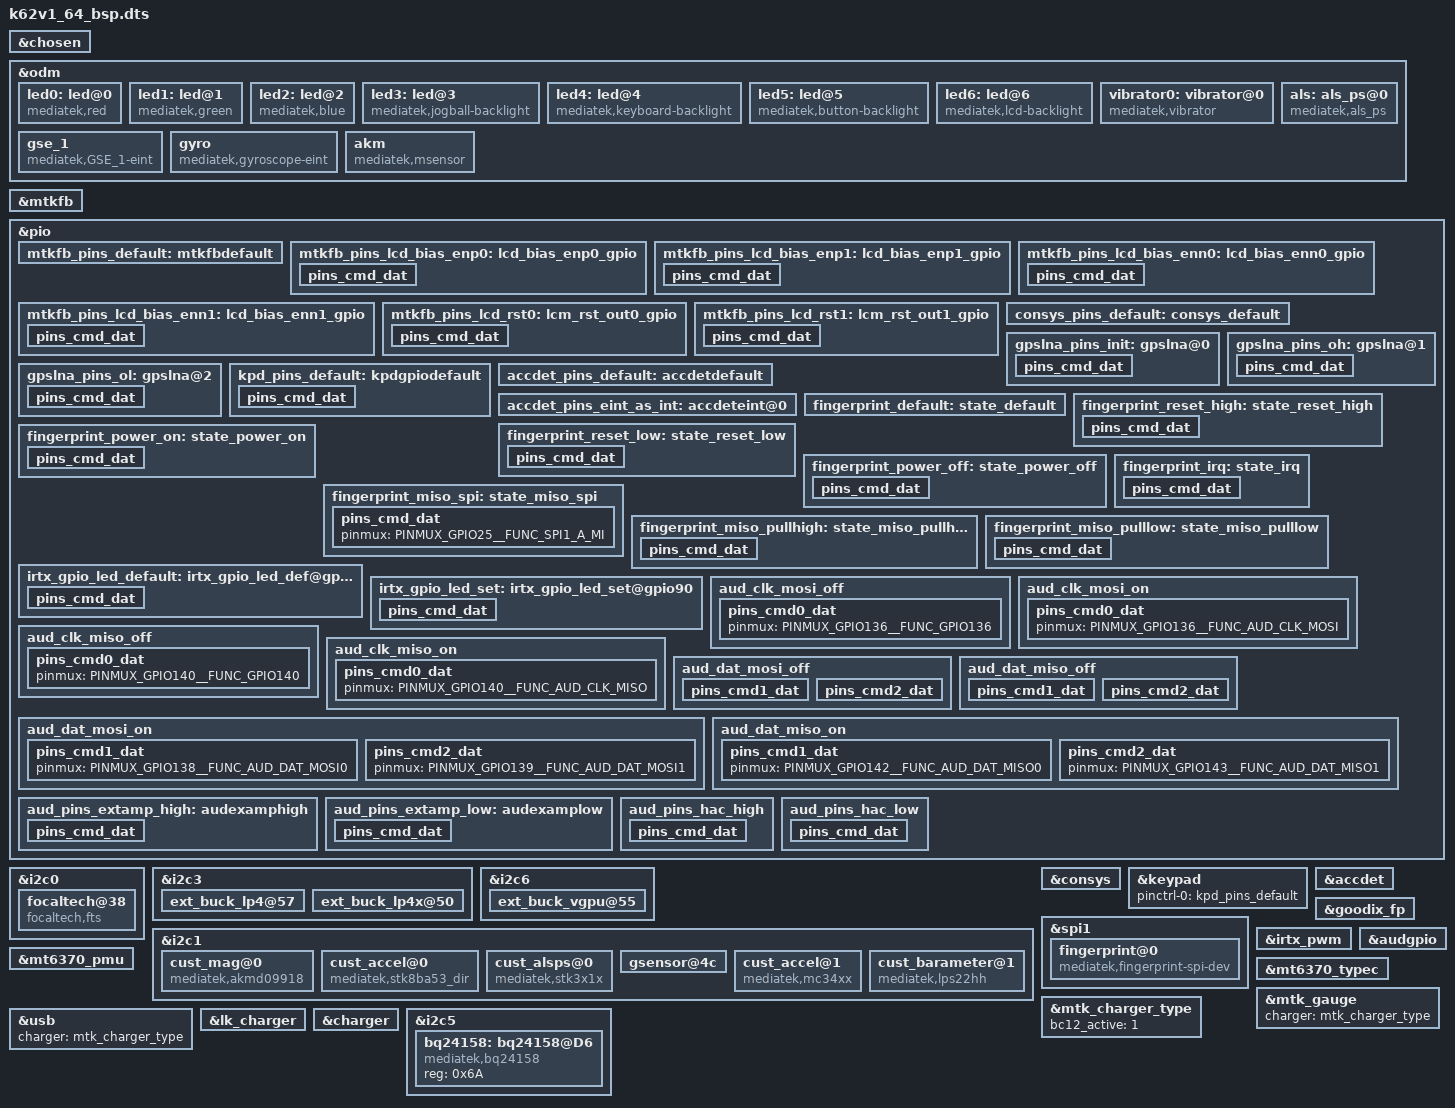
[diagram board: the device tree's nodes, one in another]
// SPDX-License-Identifier: GPL-2.0+

#include <dt-bindings/interrupt-controller/arm-gic.h>
#include <dt-bindings/interrupt-controller/irq.h>
#include <dt-bindings/pinctrl/mt6765-pinfunc.h>
#include <dt-bindings/clock/mt6765-clk.h>

/dts-v1/;
/plugin/;

/* chosen */
&chosen {

	/* fpga may has no lk, we need to specify display info here */
	/* fb buffer is reserved using this dts by memory node above */
	atag,videolfb-fb_base_h = <0x0>;
	atag,videolfb-fb_base_l = <0x5e605000>;
	atag,videolfb-islcmfound = <1>;
	/* because no lk, so lcm is not inited */
	atag,videolfb-islcm_inited = <0>;
	atag,videolfb-fps= <6000>;
	atag,videolfb-vramSize= <0x017bb000>;
	atag,videolfb-lcmname= "nt35695B_fhd_dsi_cmd_auo_rt5081_drv";
};

&odm {
	led0:led@0 {
		compatible = "mediatek,red";
		/* Begin modified by bitao.xiong for task-9796564 on 2020-08-20 */
		led_mode = <3>;
		data = <2>;
		/* End modified by bitao.xiong for task-9796564 on 2020-08-20 */
		pwm_config = <0 0 0 0 0>;
	};
	led1:led@1 {
		compatible = "mediatek,green";
		led_mode = <0>;
		data = <1>;
		pwm_config = <0 0 0 0 0>;
	};
	led2:led@2 {
		compatible = "mediatek,blue";
		led_mode = <0>;
		data = <1>;
		pwm_config = <0 0 0 0 0>;
	};
	led3:led@3 {
		compatible = "mediatek,jogball-backlight";
		led_mode = <0>;
		data = <1>;
		pwm_config = <0 0 0 0 0>;
	};
	led4:led@4 {
		compatible = "mediatek,keyboard-backlight";
		led_mode = <0>;
		data = <1>;
		pwm_config = <0 0 0 0 0>;
	};
	led5:led@5 {
		compatible = "mediatek,button-backlight";
		led_mode = <0>;
		data = <1>;
		pwm_config = <0 0 0 0 0>;
	};
//begin modified by xiongbo.huang for backlight frequency on 20200601
	led6:led@6 {
		compatible = "mediatek,lcd-backlight";
		led_mode = <5>;
		data = <1>;
		pwm_config = <0 0 0 0 0>;
	};
//end modified by xiongbo.huang for backlight frequency on 20200601
	vibrator0:vibrator@0 {
		compatible = "mediatek,vibrator";
		vib_timer = <25>;
		vib_limit = <9>;
		vib_vol= <9>;
	};

         als: als_ps@0 {
                compatible = "mediatek,als_ps";
	        interrupt-parent = <&pio>;
         	interrupts = <6 IRQ_TYPE_LEVEL_LOW 6 0>;
         	status = "okay";
         };
         gse_1: gse_1 {
         compatible = "mediatek,GSE_1-eint";
         };
         gyro: gyro {
               compatible = "mediatek,gyroscope-eint";
         };
         akm: akm{
               compatible = "mediatek,msensor";
         };
	
};

//begin add by xiongbo.huang for android r porting on 20200601
&mtkfb {
	pinctrl-names = "default", "lcd_bias_enp0_gpio", "lcd_bias_enp1_gpio","lcd_bias_enn0_gpio", "lcd_bias_enn1_gpio","lcm_rst_out0_gpio","lcm_rst_out1_gpio";
	pinctrl-0 = <&mtkfb_pins_default>;
	pinctrl-1 = <&mtkfb_pins_lcd_bias_enp0>;
	pinctrl-2 = <&mtkfb_pins_lcd_bias_enp1>;
	pinctrl-3 = <&mtkfb_pins_lcd_bias_enn0>;
	pinctrl-4 = <&mtkfb_pins_lcd_bias_enn1>;
	pinctrl-5 = <&mtkfb_pins_lcd_rst0>;
	pinctrl-6 = <&mtkfb_pins_lcd_rst1>;
	status = "okay";
};
&pio {
	mtkfb_pins_default: mtkfbdefault {
	};

	mtkfb_pins_lcd_bias_enp0: lcd_bias_enp0_gpio {
		pins_cmd_dat {
			pinmux = <PINMUX_GPIO164__FUNC_GPIO164>;
			slew-rate = <1>;
			output-low;
		};
	};

	mtkfb_pins_lcd_bias_enp1: lcd_bias_enp1_gpio {
		pins_cmd_dat {
			pinmux = <PINMUX_GPIO164__FUNC_GPIO164>;
			slew-rate = <1>;
			output-high;
		};
	};

	mtkfb_pins_lcd_bias_enn0: lcd_bias_enn0_gpio {
                   pins_cmd_dat {
                            pinmux = <PINMUX_GPIO166__FUNC_GPIO166>;
                            slew-rate = <1>;
                            output-low;
                   };
         };

         mtkfb_pins_lcd_bias_enn1: lcd_bias_enn1_gpio {
                   pins_cmd_dat {
                            pinmux = <PINMUX_GPIO166__FUNC_GPIO166>;
                            slew-rate = <1>;
                            output-high;
                   };
         };

         mtkfb_pins_lcd_rst0: lcm_rst_out0_gpio {
                   pins_cmd_dat {
                            pinmux = <PINMUX_GPIO45__FUNC_GPIO45>;
                            slew-rate = <1>;
                            output-low;
                   };
         };

         mtkfb_pins_lcd_rst1: lcm_rst_out1_gpio {
                   pins_cmd_dat {
                            pinmux = <PINMUX_GPIO45__FUNC_GPIO45>;
                            slew-rate = <1>;
                            output-high;
                   };
         };

};
&i2c0 {
		focaltech@38{
			compatible = "focaltech,fts";
			reg = <0x38>;
			interrupt-parent = <&pio>;
			interrupts = <0 IRQ_TYPE_EDGE_FALLING 0 0>;
			focaltech,reset-gpio = <&pio 46 0x0>;
			focaltech,irq-gpio = <&pio 0 0x0>;
			focaltech,max-touch-number = <5>;
			focaltech,display-coords =  <0 0 720 1440>;
			vtouch-supply = <&mt_pmic_vldo28_ldo_reg>;
			/*pinctrl-names = "pmx_ts_active","pmx_ts_suspend","pmx_ts_release";
			pinctrl-0 = <&ts_int_active &ts_reset_active>;
			pinctrl-1 = <&ts_int_suspend &ts_reset_suspend>;
			pinctrl-2 = <&ts_release>;*/

			/*
			focaltech,have-key;
			focaltech,key-number = <3>;
			focaltech,keys = <139 102 158>;
			focaltech,key-x-coords = <200 600 800>;
			focaltech,key-y-coords = <2000 2000 2000>;
			*/
		};
	};
//end add by xiongbo.huang for android r porting on 20200601
&i2c3 {
	ext_buck_lp4@57 {
		regulator-name ="ext_buck_vdd2";
		regulator-min-microvolt = <300000>;
		regulator-max-microvolt = <1300000>;
		vsel_pin = <0>;
	};

	ext_buck_lp4x@50 {
		regulator-name ="ext_buck_vddq";
		regulator-min-microvolt = <300000>;
		regulator-max-microvolt = <1300000>;
		vsel_pin = <1>;
	};
};

&i2c6 {
	ext_buck_vgpu@55 {
		regulator-name ="ext_buck_vgpu";
		regulator-min-microvolt = <300000>;
		regulator-max-microvolt = <1300000>;
		vsel_pin = <2>;
	};
};

&i2c1 {
/*  start sensor */
         cust_mag@0 {
                 compatible              = "mediatek,akmd09918";
                 /* i2c_num              = <1>; */
                 /* i2c_addr             = <0x0C 0 0 0>; */
                 direction               = <4>;
                 power_id                = <0xffff>;
                 power_vol               = <0>;
                 /* is_batch_supported   = <0>; */
         };
     	cust_accel@0 {
         compatible = "mediatek,stk8ba53_dir";
         //i2c_num = <1>;
         direction = <1>;
         power_id = <0xffff>;
         power_vol = <0>;
         firlen = <0>;
         is_batch_supported = <0>;
         };
         cust_alsps@0 {
         compatible = "mediatek,stk3x1x";
         /*i2c_num = <1>;
         i2c_addr = <0x51 0 0 0>;*/
         polling_mode_ps = <0>;
         polling_mode_als = <1>;
         power_id = <0xffff>;
         power_vol = <0>;
         als_level = <0 328 861 1377 3125 7721 7767 12621 23062 28430 33274 47116 57694 57694 65535>;
         als_value = <0 133 304 502 1004 2005 3058 5005 8008 10010 12000 16000 20000 20000 20000 20000>;
         ps_threshold_high = <26>;
         ps_threshold_low = <21>;
         is_batch_supported_ps = <0>;
         is_batch_supported_als = <0>;
         };

         gsensor@4c {
                 i2c_num = <1>;
                 direction = <6>;
                 power_id = <0xffff>;
                 power_vol = <0>;
                 firlen = <16>;
                 is_batch_supported = <1>;
         };
         cust_accel@1 {
                 compatible = "mediatek,mc34xx";
                 //i2c_num       = <1>;
                 direction = <1>;
                 power_id = <0xffff>;
                 power_vol = <0>;
                 firlen = <0>;
                 is_batch_supported = <0>;
         };

         cust_barameter@1 {
                 compatible = "mediatek,lps22hh";
		 i2c_num= <1>;
                 direction = <1>;
                 power_id = <0xffff>;
                 power_vol = <0>;
                 firlen = <1>;
                 is_batch_supported = <1>;
         };
/* end sensor */
/* end sensor */
};



//Begin modified by yaoting.wei for GNSS task 8177692 on 2019/07/29
/* CONSYS GPIO standardization */
&pio {
	consys_pins_default: consys_default {
	};
	gpslna_pins_init: gpslna@0 {
		pins_cmd_dat {
			pinmux = <PINMUX_GPIO76__FUNC_GPIO76>;
			slew-rate = <0>;
			bias-disable;
			output-low;
		};
	};
	gpslna_pins_oh: gpslna@1 {
		pins_cmd_dat {
			pinmux = <PINMUX_GPIO76__FUNC_GPIO76>;
			slew-rate = <1>;
			output-high;
		};
	};
	gpslna_pins_ol: gpslna@2 {
		pins_cmd_dat {
			pinmux = <PINMUX_GPIO76__FUNC_GPIO76>;
			slew-rate = <1>;
			output-low;
		};
	};
};
&consys {
	pinctrl-names = "default", "gps_lna_state_init",
		"gps_lna_state_oh", "gps_lna_state_ol";
	pinctrl-0 = <&consys_pins_default>;
	pinctrl-1 = <&gpslna_pins_init>;
	pinctrl-2 = <&gpslna_pins_oh>;
	pinctrl-3 = <&gpslna_pins_ol>;
	status = "okay";
};
/* CONSYS end */
//End modified by yaoting.wei for GNSS  task 8177692 on 2019/07/29

&keypad {
	pinctrl-names = "default";
	pinctrl-0 = <&kpd_pins_default>;
};

&pio {
	kpd_pins_default: kpdgpiodefault {
		pins_cmd_dat {
			pinmux = <PINMUX_GPIO93__FUNC_KPCOL0>;
			bias-pull-up = <MTK_PUPD_SET_R1R0_10>;
			output-low;
			input-schmitt-enable;
		};
	};
};


/* accdet start */
/* Begin Modified by chunyang.zhou for 7821596 :enable headset accdet config */
&accdet {
	/* accdet micbias voltage: 0x07,2.7v;0x05,2.5v;0x02,1.9v */
	accdet-mic-vol = <6>;
	headset-mode-setting = <0x500 0x500 1 0x1f0 0x2000 0x800 0x20 0x44>;
	accdet-plugout-debounce = <20>;
	/*1:ACC mode, 2:low cost without in bias, 6:low cost with in bias*/
	accdet-mic-mode = <1>;
	/* eint_level_trigger: 8,LEVEL_LOW(default);4,LEVEL_HIGH;others,LEVEL_LOW */
	headset-eint-level-pol = <8>;
	/*0--MD_MAX--UP_MAX--DW_MAX*/
	headset-three-key-threshold = <0 80 220 400>;
	headset-three-key-threshold-CDD = <0 121 192 600>;
	/*0--MD_MAX--VOICE_MAX--UP_MAX--DW_MAX*/
	headset-four-key-threshold = <0 58 121 192 400>;
	pinctrl-names = "default", "state_eint_as_int";
	pinctrl-0 = <&accdet_pins_default>;
	pinctrl-1 = <&accdet_pins_eint_as_int>;
	status = "okay";
};
/* End Modified by chunyang.zhou for 7821596 :enable headset accdet config */
&pio {
	accdet_pins_default: accdetdefault {
	};
	accdet_pins_eint_as_int: accdeteint@0 {
	};
};
/* accdet end */
/*End   Modified by fuhua.wang for audio-bring-up on 2019.07.31 task_id: 8188551 */

/* FINGERPRINT start */

/* FINGERPRINT end */

/* FINGERPRINT start */
/* Begin to modified by yuduan.xie on 2019.07.31 for 8177729 */
&spi1 {
	#address-cells = <1>;
	#size-cells = <0>;
	fingerprint@0 {
		compatible = "mediatek,fingerprint-spi-dev";
		reg = <0>;
		spi-max-frequency = <12000000>;
		netlink-event = <31>;
		status = "okay";
	};
};
&goodix_fp{
	pinctrl-names = "fp_default", "fp_reset_high", "fp_reset_low", "fp_power_on", "fp_power_off", "fp_irq", "miso_spi", "miso_pullhigh", "miso_pulllow";
	pinctrl-0 = <&fingerprint_default>;
	pinctrl-1 = <&fingerprint_reset_high>;
	pinctrl-2 = <&fingerprint_reset_low>;
	pinctrl-3 = <&fingerprint_power_on>;
	pinctrl-4 = <&fingerprint_power_off>;
	pinctrl-5 = <&fingerprint_irq>;

	pinctrl-6 = <&fingerprint_miso_spi>;
	pinctrl-7 = <&fingerprint_miso_pullhigh>;
	pinctrl-8 = <&fingerprint_miso_pulllow>;

	status = "okay";
};

&pio {
	fingerprint_default: state_default {

	};

	fingerprint_reset_high: state_reset_high{
		pins_cmd_dat {
			pinmux = <PINMUX_GPIO14__FUNC_GPIO14>;
			slew-rate = <1>;
			output-high;
		};
	};

	fingerprint_reset_low: state_reset_low{
		pins_cmd_dat {
			pinmux = <PINMUX_GPIO14__FUNC_GPIO14>;
			slew-rate = <1>;
			output-low;
		};
	};

	fingerprint_power_on: state_power_on{
		pins_cmd_dat {
			pinmux = <PINMUX_GPIO21__FUNC_GPIO21>;
			slew-rate = <1>;
			output-high;
		};
	};

	fingerprint_power_off: state_power_off{
		pins_cmd_dat {
			pinmux = <PINMUX_GPIO21__FUNC_GPIO21>;
			slew-rate = <1>;
			output-low;
		};
	};

	fingerprint_irq: state_irq{
		pins_cmd_dat {
			pinmux = <PINMUX_GPIO13__FUNC_GPIO13>;
			slew-rate = <0>;
			bias-pull-down = <11>;
		};
	};

	fingerprint_miso_spi: state_miso_spi {
		pins_cmd_dat {
			pinmux = <PINMUX_GPIO25__FUNC_SPI1_A_MI>;
		};
	};
	fingerprint_miso_pullhigh: state_miso_pullhigh {
		pins_cmd_dat {
			pinmux = <PINMUX_GPIO25__FUNC_GPIO25>;
			slew-rate = <1>;
			output-high;
		};
	};
	fingerprint_miso_pulllow: state_miso_pulllow {
		pins_cmd_dat {
			pinmux = <PINMUX_GPIO25__FUNC_GPIO25>;
			slew-rate = <1>;
			output-low;
		};
	};
};
/* End to modified by yuduan.xie on 2019.07.31 for 8177729 */
/* FINGERPRINT end */

/* IRTX GPIO end */
&irtx_pwm {
	pinctrl-names = "irtx_gpio_led_default", "irtx_gpio_led_set";
	pinctrl-0 = <&irtx_gpio_led_default>;
	pinctrl-1 = <&irtx_gpio_led_set>;
	status = "okay";
};
&pio {
	irtx_gpio_led_default:irtx_gpio_led_def@gpio90 {
		pins_cmd_dat {
			pinmux = <PINMUX_GPIO90__FUNC_GPIO90>;
			slew-rate = <1>;
			bias-disable;
			output-low;
			input-schmitt-enable = <0>;
		};
	};

	irtx_gpio_led_set:irtx_gpio_led_set@gpio90 {
		pins_cmd_dat {
			pinmux = <PINMUX_GPIO90__FUNC_PWM0>;
			slew-rate = <1>;
			output-high;
		};
	};
};
/* IRTX GPIO Settings -End */

/*Begin Modified by fuhua.wang for audio-bring-up on 2019.07.31 task_id: 8188551 */
/* AUDIO GPIO standardization */
/* Added By chunyang.zhou for task 7821596 : Add tokyo & soual audio config */
&audgpio {
	pinctrl-names = "aud_clk_mosi_off",
			"aud_clk_mosi_on",
			"aud_clk_miso_off",
			"aud_clk_miso_on",
			"aud_dat_mosi_off",
			"aud_dat_mosi_on",
			"aud_dat_miso_off",
			"aud_dat_miso_on",
			"extamp-pullhigh",
			"extamp-pulllow",
			"hac-pullhigh",
			"hac-pulllow";
	pinctrl-0 = <&aud_clk_mosi_off>;
	pinctrl-1 = <&aud_clk_mosi_on>;
	pinctrl-2 = <&aud_clk_miso_off>;
	pinctrl-3 = <&aud_clk_miso_on>;
	pinctrl-4 = <&aud_dat_mosi_off>;
	pinctrl-5 = <&aud_dat_mosi_on>;
	pinctrl-6 = <&aud_dat_miso_off>;
	pinctrl-7 = <&aud_dat_miso_on>;
	pinctrl-8 = <&aud_pins_extamp_high>;
	pinctrl-9 = <&aud_pins_extamp_low>;
	pinctrl-10 = <&aud_pins_hac_high>;
	pinctrl-11 = <&aud_pins_hac_low>;
	status = "okay";
};

&pio {
	aud_clk_mosi_off: aud_clk_mosi_off {
		pins_cmd0_dat {
			pinmux = <PINMUX_GPIO136__FUNC_GPIO136>;
		};
	};

	aud_clk_mosi_on: aud_clk_mosi_on {
		pins_cmd0_dat {
			pinmux = <PINMUX_GPIO136__FUNC_AUD_CLK_MOSI>;
		};
	};

	aud_clk_miso_off: aud_clk_miso_off {
		pins_cmd0_dat {
			pinmux = <PINMUX_GPIO140__FUNC_GPIO140>;
		};
	};

	aud_clk_miso_on: aud_clk_miso_on {
		pins_cmd0_dat {
			pinmux = <PINMUX_GPIO140__FUNC_AUD_CLK_MISO>;
		};
	};

	aud_dat_mosi_off: aud_dat_mosi_off {
		pins_cmd1_dat {
			pinmux = <PINMUX_GPIO138__FUNC_GPIO138>;
			input-enable;
			slew-rate = <0>;
			bias-disable;
		};
		pins_cmd2_dat {
			pinmux = <PINMUX_GPIO139__FUNC_GPIO139>;
			input-enable;
			slew-rate = <0>;
			bias-disable;
		};
	};

	aud_dat_mosi_on: aud_dat_mosi_on {
		pins_cmd1_dat {
			pinmux = <PINMUX_GPIO138__FUNC_AUD_DAT_MOSI0>;
		};
		pins_cmd2_dat {
			pinmux = <PINMUX_GPIO139__FUNC_AUD_DAT_MOSI1>;
		};
	};

	aud_dat_miso_off: aud_dat_miso_off {
		pins_cmd1_dat {
			pinmux = <PINMUX_GPIO142__FUNC_GPIO142>;
			input-enable;
			slew-rate = <0>;
			bias-disable;
		};
		pins_cmd2_dat {
			pinmux = <PINMUX_GPIO143__FUNC_GPIO143>;
			input-enable;
			slew-rate = <0>;
			bias-disable;
		};
	};

	aud_dat_miso_on: aud_dat_miso_on {
		pins_cmd1_dat {
			pinmux = <PINMUX_GPIO142__FUNC_AUD_DAT_MISO0>;
		};
		pins_cmd2_dat {
			pinmux = <PINMUX_GPIO143__FUNC_AUD_DAT_MISO1>;
		};
	};

	aud_pins_extamp_high: audexamphigh {
		pins_cmd_dat {
			pinmux = <PINMUX_GPIO153__FUNC_GPIO153>;
			slew-rate = <1>;
			output-high;
		};
	};
	aud_pins_extamp_low: audexamplow {
		pins_cmd_dat {
			pinmux = <PINMUX_GPIO153__FUNC_GPIO153>;
			slew-rate = <1>;
			output-low;
		};
	};
	aud_pins_hac_high: aud_pins_hac_high {
		pins_cmd_dat {
			pinmux = <PINMUX_GPIO154__FUNC_GPIO154>;
			slew-rate = <1>;
			output-high;
		};
	};
	aud_pins_hac_low: aud_pins_hac_low {
		pins_cmd_dat {
			pinmux = <PINMUX_GPIO154__FUNC_GPIO154>;
			slew-rate = <1>;
			output-low;
		};
	};
};
/*begin add by fuhu AWINIC AW881XX Smart PA for task 8740652*/
/* End By chunyang.zhou for task 7821596 : Add tokyo & soual audio config */
/* AUDIO end */
/*End   Modified by fuhua.wang for audio-bring-up on 2019.07.31 task_id: 8188551 */

&mt6370_pmu {
	mt6370,intr_gpio_num = <11>; /* direct defined GPIO num */
	mt6370,intr_gpio = <&pio 11 0x0>;
};

&mt6370_typec {
	mt6370pd,intr_gpio_num = <41>; /* direct defined GPIO num */
	mt6370pd,intr_gpio = <&pio 41 0x0>;
};


&mtk_gauge {
	charger = <&mtk_charger_type>;
};

&mtk_charger_type {
	bc12_active = <1>;
};

&usb {
	charger = <&mtk_charger_type>;
};

&lk_charger {
	/delete-property/enable_pe_plus;
	/delete-property/enable_pd20_reset;
	/delete-property/power_path_support;

	ac_charger_current = <500000>;
	charging_host_charger_current = <500000>;
	led_brightness = <127>;
	blinking_times = <6>;
	blinking_period = <1500>;
};

&charger {
	charger = <&mtk_charger_type>;
	/delete-property/enable_pe_plus;
	/delete-property/enable_pe_2;
	/delete-property/enable_pe_3;
	/delete-property/enable_pe_4;
	/delete-property/enable_type_c;
	/delete-property/power_path_support;
	ac_charger_input_current = <1000000>;
	ac_charger_current = <1050000>;
	battery_cv = <4400000>;
	enable_sw_jeita;
	/* sw jeita */
	jeita_temp_above_t4_cv = <4100000>;
	jeita_temp_t3_to_t4_cv = <4100000>;
	jeita_temp_t2_to_t3_cv = <4400000>;
	jeita_temp_t1_to_t2_cv = <4400000>;
	jeita_temp_t0_to_t1_cv = <4400000>;
	jeita_temp_below_t0_cv = <4400000>;
	jeita_temp_t3_to_t4_cc = <1050000>; /* 43 - 55 Degree */
	jeita_temp_t1_to_t2_cc = <864000>; /* 0 - 10 Degree */

	temp_t4_thres = <55>;
	temp_t4_thres_minus_x_degree = <51>;
	temp_t3_thres = <42>;
	temp_t3_thres_minus_x_degree = <43>;
	temp_t2_thres = <11>;
	temp_t2_thres_plus_x_degree = <10>;
	temp_t1_thres = <1>;
	temp_t1_thres_plus_x_degree = <0>;
	temp_t0_thres = <1>;
	temp_t0_thres_plus_x_degree = <0>;
	temp_neg_10_thres = <1>;
};

&i2c5 {
       bq24158:bq24158@D6{
               compatible = "mediatek,bq24158";
               reg = <0x6A>;
               status = "okay";
       };
};

#include "k62v1_64_bsp/cust.dtsi"
#include "mediatek/cust_mt6765_camera.dtsi"
#include "mediatek/cust_mt6765_touch_1080x1920.dtsi"
/*End of this file, DO NOT ADD ANYTHING HERE*/
